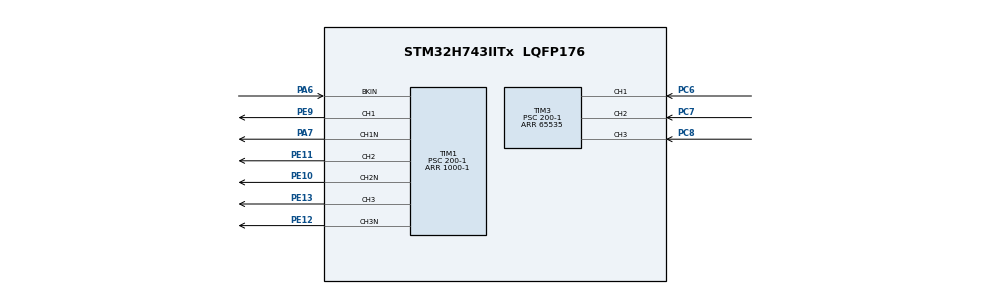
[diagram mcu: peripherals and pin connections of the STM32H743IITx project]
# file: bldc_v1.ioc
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Mcu.Family=STM32H7
Mcu.Name=STM32H743IITx
Mcu.Package=LQFP176
NVIC.PriorityGroup=NVIC_PRIORITYGROUP_4
PA6.Mode=Activate-Break-Input
PA6.Signal=TIM1_BKIN
PA7.GPIO_Speed=GPIO_SPEED_FREQ_HIGH
PA7.Mode=PWM Generation1 CH1 CH1N
PA7.Signal=TIM1_CH1N
PC6.GPIO_Speed=GPIO_SPEED_FREQ_HIGH
PC6.Signal=S_TIM3_CH1
PC7.GPIO_Speed=GPIO_SPEED_FREQ_HIGH
PC7.Signal=S_TIM3_CH2
PC8.GPIO_Speed=GPIO_SPEED_FREQ_HIGH
PC8.Signal=S_TIM3_CH3
PE10.GPIO_Speed=GPIO_SPEED_FREQ_HIGH
PE10.Mode=PWM Generation2 CH2 CH2N
PE10.Signal=TIM1_CH2N
PE11.GPIO_Speed=GPIO_SPEED_FREQ_HIGH
PE11.Signal=S_TIM1_CH2
PE12.GPIO_Speed=GPIO_SPEED_FREQ_HIGH
PE12.Mode=PWM Generation3 CH3 CH3N
PE12.Signal=TIM1_CH3N
PE13.GPIO_Speed=GPIO_SPEED_FREQ_HIGH
PE13.Signal=S_TIM1_CH3
PE9.GPIO_Speed=GPIO_SPEED_FREQ_MEDIUM
PE9.Signal=S_TIM1_CH1
PH0-OSC_IN\ (PH0).Mode=HSE-External-Oscillator
PH0-OSC_IN\ (PH0).Signal=RCC_OSC_IN
PH1-OSC_OUT\ (PH1).Mode=HSE-External-Oscillator
PH1-OSC_OUT\ (PH1).Signal=RCC_OSC_OUT
ProjectManager.HeapSize=0x200
ProjectManager.StackSize=0x400
ProjectManager.TargetToolchain=MDK-ARM V5.27
RCC.ADCFreq_Value=129000000
RCC.APB1Freq_Value=100000000
RCC.APB2Freq_Value=100000000
RCC.APB3Freq_Value=100000000
RCC.APB4Freq_Value=100000000
RCC.CortexFreq_Value=400000000
RCC.D1PPRE=RCC_APB3_DIV2
RCC.D2PPRE1=RCC_APB1_DIV2
RCC.D2PPRE2=RCC_APB2_DIV2
RCC.D3PPRE=RCC_APB4_DIV2
RCC.DIVM1=4
RCC.DIVN1=50
RCC.HCLKFreq_Value=200000000
RCC.HPRE=RCC_HCLK_DIV2
RCC.PLL2FRACN=0
RCC.PLL3FRACN=0
RCC.PLLFRACN=0
RCC.SYSCLKFreq_VALUE=400000000
RCC.SYSCLKSource=RCC_SYSCLKSOURCE_PLLCLK
RCC.USBFreq_Value=400000000
SH.S_TIM1_CH1.0=TIM1_CH1,PWM Generation1 CH1 CH1N
SH.S_TIM1_CH2.0=TIM1_CH2,PWM Generation2 CH2 CH2N
SH.S_TIM1_CH3.0=TIM1_CH3,PWM Generation3 CH3 CH3N
SH.S_TIM3_CH1.0=TIM3_CH1,Xored_Inputs_Hall_Sensor_Interface
SH.S_TIM3_CH2.0=TIM3_CH2,Xored_Inputs_Hall_Sensor_Interface
SH.S_TIM3_CH3.0=TIM3_CH3,Xored_Inputs_Hall_Sensor_Interface
TIM1.AutoReloadPreload=TIM_AUTORELOAD_PRELOAD_ENABLE
TIM1.Channel-PWM\ Generation1\ CH1\ CH1N=TIM_CHANNEL_1
TIM1.Channel-PWM\ Generation2\ CH2\ CH2N=TIM_CHANNEL_2
TIM1.Channel-PWM\ Generation3\ CH3\ CH3N=TIM_CHANNEL_3
TIM1.DeadTime=90
TIM1.Period=1000-1
TIM1.Prescaler=200-1
TIM1.Pulse-PWM\ Generation1\ CH1\ CH1N=500
TIM1.Pulse-PWM\ Generation2\ CH2\ CH2N=500
TIM1.Pulse-PWM\ Generation3\ CH3\ CH3N=500
TIM3.AutoReloadPreload=TIM_AUTORELOAD_PRELOAD_ENABLE
TIM3.IC1Filter=10
TIM3.Period=65535
TIM3.Prescaler=200-1
VP_TIM1_VS_ClockSourceINT.Mode=Internal
VP_TIM3_VS_ClockSourceINT.Mode=Internal
board=custom

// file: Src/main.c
/* USER CODE BEGIN Header */
/**
  ******************************************************************************
  * @file           : main.c
  * @brief          : Main program body
  ******************************************************************************
  * @attention
  *
  * <h2><center>&copy; Copyright (c) 2020 STMicroelectronics.
  * All rights reserved.</center></h2>
  *
  * This software component is licensed by ST under BSD 3-Clause license,
  * the "License"; You may not use this file except in compliance with the
  * License. You may obtain a copy of the License at:
  *                        opensource.org/licenses/BSD-3-Clause
  *
  ******************************************************************************
  */
/* USER CODE END Header */

#include "main.h"
#include "tim.h"
#include "gpio.h"
#include "key.h"

void SystemClock_Config(void);

int main(void)
{

  /* MCU Configuration--------------------------------------------------------*/

  /* Reset of all peripherals, Initializes the Flash interface and the Systick. */
  HAL_Init();

  /* Configure the system clock */
  SystemClock_Config();

  /* Initialize all configured peripherals */
  MX_GPIO_Init();
  MX_TIM3_Init();
  MX_TIM1_Init();
  /* USER CODE BEGIN 2 */

//	HAL_TIM_PWM_Start(&htim1,TIM_CHANNEL_1);
//	HAL_TIMEx_PWMN_Start(&htim1,TIM_CHANNEL_1);
//
//	HAL_TIM_PWM_Start(&htim1,TIM_CHANNEL_2);
//	HAL_TIMEx_PWMN_Start(&htim1,TIM_CHANNEL_2);
////
//	HAL_TIM_PWM_Start(&htim1,TIM_CHANNEL_3);
//	HAL_TIMEx_PWMN_Start(&htim1,TIM_CHANNEL_3);

  /* USER CODE END 2 */

  /* Infinite loop */
  while (1)
  {

    /* USER CODE BEGIN 3 */
		 if( Key_Scan(KEY1_GPIO_PORT,KEY1_PIN) == KEY_ON  )
		{
			/*�������*/
			Enable_BLDC();
		}

    if( Key_Scan(KEY2_GPIO_PORT,KEY2_PIN) == KEY_ON  )
		{
			/*���ֹͣ*/
			Disable_BLDC();
		}

  }
  /* USER CODE END 3 */
}

void SystemClock_Config(void)
{
  RCC_OscInitTypeDef RCC_OscInitStruct = {0};
  RCC_ClkInitTypeDef RCC_ClkInitStruct = {0};

  /** Supply configuration update enable
  */
  HAL_PWREx_ConfigSupply(PWR_LDO_SUPPLY);
  /** Configure the main internal regulator output voltage
  */
  __HAL_PWR_VOLTAGESCALING_CONFIG(PWR_REGULATOR_VOLTAGE_SCALE1);

  while(!__HAL_PWR_GET_FLAG(PWR_FLAG_VOSRDY)) {}
  /** Initializes the CPU, AHB and APB busses clocks
  */
  RCC_OscInitStruct.OscillatorType = RCC_OSCILLATORTYPE_HSI;
  RCC_OscInitStruct.HSIState = RCC_HSI_DIV1;
  RCC_OscInitStruct.HSICalibrationValue = RCC_HSICALIBRATION_DEFAULT;
  RCC_OscInitStruct.PLL.PLLState = RCC_PLL_ON;
  RCC_OscInitStruct.PLL.PLLSource = RCC_PLLSOURCE_HSI;
  RCC_OscInitStruct.PLL.PLLM = 4;
  RCC_OscInitStruct.PLL.PLLN = 50;
  RCC_OscInitStruct.PLL.PLLP = 2;
  RCC_OscInitStruct.PLL.PLLQ = 2;
  RCC_OscInitStruct.PLL.PLLR = 2;
  RCC_OscInitStruct.PLL.PLLRGE = RCC_PLL1VCIRANGE_3;
  RCC_OscInitStruct.PLL.PLLVCOSEL = RCC_PLL1VCOWIDE;
  RCC_OscInitStruct.PLL.PLLFRACN = 0;
  if (HAL_RCC_OscConfig(&RCC_OscInitStruct) != HAL_OK)
  {
    Error_Handler();
  }
  /** Initializes the CPU, AHB and APB busses clocks
  */
  RCC_ClkInitStruct.ClockType = RCC_CLOCKTYPE_HCLK|RCC_CLOCKTYPE_SYSCLK
                              |RCC_CLOCKTYPE_PCLK1|RCC_CLOCKTYPE_PCLK2
                              |RCC_CLOCKTYPE_D3PCLK1|RCC_CLOCKTYPE_D1PCLK1;
  RCC_ClkInitStruct.SYSCLKSource = RCC_SYSCLKSOURCE_PLLCLK;
  RCC_ClkInitStruct.SYSCLKDivider = RCC_SYSCLK_DIV1;
  RCC_ClkInitStruct.AHBCLKDivider = RCC_HCLK_DIV2;
  RCC_ClkInitStruct.APB3CLKDivider = RCC_APB3_DIV2;
  RCC_ClkInitStruct.APB1CLKDivider = RCC_APB1_DIV2;
  RCC_ClkInitStruct.APB2CLKDivider = RCC_APB2_DIV2;
  RCC_ClkInitStruct.APB4CLKDivider = RCC_APB4_DIV2;

  if (HAL_RCC_ClockConfig(&RCC_ClkInitStruct, FLASH_LATENCY_2) != HAL_OK)
  {
    Error_Handler();
  }
}

void Error_Handler(void)
{
}

/************************ (C) COPYRIGHT STMicroelectronics *****END OF FILE****/
